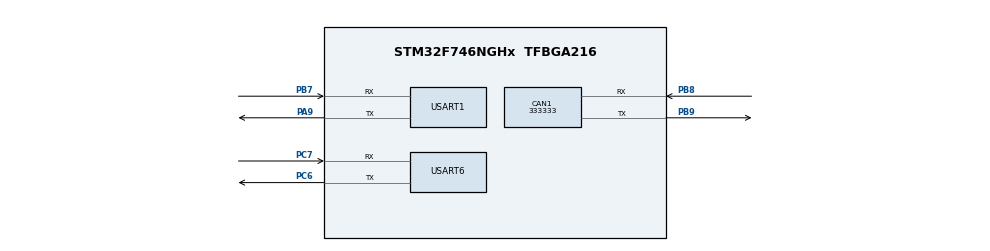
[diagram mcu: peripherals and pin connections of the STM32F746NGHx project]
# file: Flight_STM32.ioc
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CAN1.CalculateBaudRate=333333
CAN1.CalculateTimeBit=3000
CAN1.CalculateTimeQuantum=1000.0
CORTEX_M7.default_mode_Activation=1
Mcu.Family=STM32F7
Mcu.Name=STM32F746NGHx
Mcu.Package=TFBGA216
NVIC.PriorityGroup=NVIC_PRIORITYGROUP_4
NVIC.TIM1_UP_TIM10_IRQn=true\:15\:0\:false\:false\:true\:false\:true\:true
NVIC.TimeBase=TIM1_UP_TIM10_IRQn
NVIC.TimeBaseIP=TIM1
PA9.Mode=Asynchronous
PA9.Signal=USART1_TX
PB7.Mode=Asynchronous
PB7.Signal=USART1_RX
PB8.Mode=CAN_Activate
PB8.Signal=CAN1_RX
PB9.Mode=CAN_Activate
PB9.Signal=CAN1_TX
PC6.Mode=Asynchronous
PC6.Signal=USART6_TX
PC7.Mode=Asynchronous
PC7.Signal=USART6_RX
ProjectManager.HeapSize=0x200
ProjectManager.StackSize=0x400
ProjectManager.TargetToolchain=STM32CubeIDE
RCC.HSE_VALUE=25000000
RCC.HSI_VALUE=16000000
RCC.LSE_VALUE=32768
RCC.USBFreq_Value=96000000
RCC.VCOOutputFreq_Value=192000000
USART1.VirtualMode-Asynchronous=VM_ASYNC
USART6.VirtualMode-Asynchronous=VM_ASYNC
VP_SYS_VS_tim1.Mode=TIM1
board=custom

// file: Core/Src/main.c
/* USER CODE BEGIN Header */
/**
  ******************************************************************************
  * @file           : main.c
  * @brief          : Main program body
  ******************************************************************************
  * @attention
  *
  * Copyright (c) 2025 STMicroelectronics.
  * All rights reserved.
  *
  * This software is licensed under terms that can be found in the LICENSE file
  * in the root directory of this software component.
  * If no LICENSE file comes with this software, it is provided AS-IS.
  *
  ******************************************************************************
  */
/* USER CODE END Header */
#include "main.h"

/* USER CODE BEGIN Includes */
#include "printf.h"
/* USER CODE END Includes */

CAN_HandleTypeDef hcan1;

void SystemClock_Config(void);
static void MPU_Config(void);
static void MX_GPIO_Init(void);
static void MX_USART1_UART_Init(void);
static void MX_USART6_UART_Init(void);
static void MX_CAN1_Init(void);

int main(void)
{

  /* MPU Configuration--------------------------------------------------------*/
  MPU_Config();

  /* MCU Configuration--------------------------------------------------------*/

  /* Reset of all peripherals, Initializes the Flash interface and the Systick. */
  HAL_Init();

  /* Configure the system clock */
  SystemClock_Config();

  /* Initialize all configured peripherals */
  MX_GPIO_Init();
  MX_USART1_UART_Init();
  MX_USART6_UART_Init();
  MX_CAN1_Init();

  /* Infinite loop */
  /* USER CODE BEGIN WHILE */
  app_main();
  while (1)
  {
    /* USER CODE END WHILE */

  }
}

void SystemClock_Config(void)
{
  LL_FLASH_SetLatency(LL_FLASH_LATENCY_0);
  while(LL_FLASH_GetLatency()!= LL_FLASH_LATENCY_0)
  {
  }
  LL_PWR_SetRegulVoltageScaling(LL_PWR_REGU_VOLTAGE_SCALE3);
  LL_PWR_DisableOverDriveMode();
  LL_RCC_HSI_SetCalibTrimming(16);
  LL_RCC_HSI_Enable();

   /* Wait till HSI is ready */
  while(LL_RCC_HSI_IsReady() != 1)
  {

  }
  LL_RCC_SetAHBPrescaler(LL_RCC_SYSCLK_DIV_1);
  LL_RCC_SetAPB1Prescaler(LL_RCC_APB1_DIV_1);
  LL_RCC_SetAPB2Prescaler(LL_RCC_APB2_DIV_1);
  LL_RCC_SetSysClkSource(LL_RCC_SYS_CLKSOURCE_HSI);

   /* Wait till System clock is ready */
  while(LL_RCC_GetSysClkSource() != LL_RCC_SYS_CLKSOURCE_STATUS_HSI)
  {

  }
  LL_SetSystemCoreClock(16000000);

   /* Update the time base */
//  if (HAL_InitTick (TICK_INT_PRIORITY) != HAL_OK)
//  {
//    Error_Handler();
//  }

   /* Set Timers Clock Prescalers */
//  LL_RCC_SetTIMPrescaler(LL_RCC_TIM_PRESCALER_TWICE);
}

static void MX_CAN1_Init(void)
{

  hcan1.Instance = CAN1;
  hcan1.Init.Prescaler = 16;
  hcan1.Init.Mode = CAN_MODE_NORMAL;
  hcan1.Init.SyncJumpWidth = CAN_SJW_1TQ;
  hcan1.Init.TimeSeg1 = CAN_BS1_1TQ;
  hcan1.Init.TimeSeg2 = CAN_BS2_1TQ;
  hcan1.Init.TimeTriggeredMode = DISABLE;
  hcan1.Init.AutoBusOff = DISABLE;
  hcan1.Init.AutoWakeUp = DISABLE;
  hcan1.Init.AutoRetransmission = DISABLE;
  hcan1.Init.ReceiveFifoLocked = DISABLE;
  hcan1.Init.TransmitFifoPriority = DISABLE;
  if (HAL_CAN_Init(&hcan1) != HAL_OK)
  {
    Error_Handler();
  }

}

static void MX_USART1_UART_Init(void)
{

  LL_USART_InitTypeDef USART_InitStruct = {0};

  LL_GPIO_InitTypeDef GPIO_InitStruct = {0};

  LL_RCC_SetUSARTClockSource(LL_RCC_USART1_CLKSOURCE_PCLK2);

  /* Peripheral clock enable */
  LL_APB2_GRP1_EnableClock(LL_APB2_GRP1_PERIPH_USART1);

  LL_AHB1_GRP1_EnableClock(LL_AHB1_GRP1_PERIPH_GPIOB);
  LL_AHB1_GRP1_EnableClock(LL_AHB1_GRP1_PERIPH_GPIOA);
  /**USART1 GPIO Configuration
  PB7   ------> USART1_RX
  PA9   ------> USART1_TX
  */
  GPIO_InitStruct.Pin = LL_GPIO_PIN_7;
  GPIO_InitStruct.Mode = LL_GPIO_MODE_ALTERNATE;
  GPIO_InitStruct.Speed = LL_GPIO_SPEED_FREQ_VERY_HIGH;
  GPIO_InitStruct.OutputType = LL_GPIO_OUTPUT_PUSHPULL;
  GPIO_InitStruct.Pull = LL_GPIO_PULL_NO;
  GPIO_InitStruct.Alternate = LL_GPIO_AF_7;
  LL_GPIO_Init(GPIOB, &GPIO_InitStruct);

  GPIO_InitStruct.Pin = LL_GPIO_PIN_9;
  GPIO_InitStruct.Mode = LL_GPIO_MODE_ALTERNATE;
  GPIO_InitStruct.Speed = LL_GPIO_SPEED_FREQ_VERY_HIGH;
  GPIO_InitStruct.OutputType = LL_GPIO_OUTPUT_PUSHPULL;
  GPIO_InitStruct.Pull = LL_GPIO_PULL_NO;
  GPIO_InitStruct.Alternate = LL_GPIO_AF_7;
  LL_GPIO_Init(GPIOA, &GPIO_InitStruct);

  USART_InitStruct.BaudRate = 115200;
  USART_InitStruct.DataWidth = LL_USART_DATAWIDTH_8B;
  USART_InitStruct.StopBits = LL_USART_STOPBITS_1;
  USART_InitStruct.Parity = LL_USART_PARITY_NONE;
  USART_InitStruct.TransferDirection = LL_USART_DIRECTION_TX_RX;
  USART_InitStruct.HardwareFlowControl = LL_USART_HWCONTROL_NONE;
  USART_InitStruct.OverSampling = LL_USART_OVERSAMPLING_16;
  LL_USART_Init(USART1, &USART_InitStruct);
  LL_USART_ConfigAsyncMode(USART1);
  LL_USART_Enable(USART1);

}

static void MX_USART6_UART_Init(void)
{

  LL_USART_InitTypeDef USART_InitStruct = {0};

  LL_GPIO_InitTypeDef GPIO_InitStruct = {0};

  LL_RCC_SetUSARTClockSource(LL_RCC_USART6_CLKSOURCE_PCLK2);

  /* Peripheral clock enable */
  LL_APB2_GRP1_EnableClock(LL_APB2_GRP1_PERIPH_USART6);

  LL_AHB1_GRP1_EnableClock(LL_AHB1_GRP1_PERIPH_GPIOC);
  /**USART6 GPIO Configuration
  PC7   ------> USART6_RX
  PC6   ------> USART6_TX
  */
  GPIO_InitStruct.Pin = LL_GPIO_PIN_7;
  GPIO_InitStruct.Mode = LL_GPIO_MODE_ALTERNATE;
  GPIO_InitStruct.Speed = LL_GPIO_SPEED_FREQ_VERY_HIGH;
  GPIO_InitStruct.OutputType = LL_GPIO_OUTPUT_PUSHPULL;
  GPIO_InitStruct.Pull = LL_GPIO_PULL_NO;
  GPIO_InitStruct.Alternate = LL_GPIO_AF_8;
  LL_GPIO_Init(GPIOC, &GPIO_InitStruct);

  GPIO_InitStruct.Pin = LL_GPIO_PIN_6;
  GPIO_InitStruct.Mode = LL_GPIO_MODE_ALTERNATE;
  GPIO_InitStruct.Speed = LL_GPIO_SPEED_FREQ_VERY_HIGH;
  GPIO_InitStruct.OutputType = LL_GPIO_OUTPUT_PUSHPULL;
  GPIO_InitStruct.Pull = LL_GPIO_PULL_NO;
  GPIO_InitStruct.Alternate = LL_GPIO_AF_8;
  LL_GPIO_Init(GPIOC, &GPIO_InitStruct);

  USART_InitStruct.BaudRate = 115200;
  USART_InitStruct.DataWidth = LL_USART_DATAWIDTH_8B;
  USART_InitStruct.StopBits = LL_USART_STOPBITS_1;
  USART_InitStruct.Parity = LL_USART_PARITY_NONE;
  USART_InitStruct.TransferDirection = LL_USART_DIRECTION_TX_RX;
  USART_InitStruct.HardwareFlowControl = LL_USART_HWCONTROL_NONE;
  USART_InitStruct.OverSampling = LL_USART_OVERSAMPLING_16;
  LL_USART_Init(USART6, &USART_InitStruct);
  LL_USART_ConfigAsyncMode(USART6);
  LL_USART_Enable(USART6);

}

static void MX_GPIO_Init(void)
{

  /* GPIO Ports Clock Enable */
  LL_AHB1_GRP1_EnableClock(LL_AHB1_GRP1_PERIPH_GPIOB);
  LL_AHB1_GRP1_EnableClock(LL_AHB1_GRP1_PERIPH_GPIOA);
  LL_AHB1_GRP1_EnableClock(LL_AHB1_GRP1_PERIPH_GPIOC);

}

 /* MPU Configuration */

void MPU_Config(void)
{

  /* Disables the MPU */
  LL_MPU_Disable();

  /** Initializes and configures the Region and the memory to be protected
  */
  LL_MPU_ConfigRegion(LL_MPU_REGION_NUMBER0, 0x87, 0x0, LL_MPU_REGION_SIZE_4GB|LL_MPU_TEX_LEVEL0|LL_MPU_REGION_NO_ACCESS|LL_MPU_INSTRUCTION_ACCESS_DISABLE|LL_MPU_ACCESS_SHAREABLE|LL_MPU_ACCESS_NOT_CACHEABLE|LL_MPU_ACCESS_NOT_BUFFERABLE);
  /* Enables the MPU */
  LL_MPU_Enable(LL_MPU_CTRL_PRIVILEGED_DEFAULT);

}

void HAL_TIM_PeriodElapsedCallback(TIM_HandleTypeDef *htim)
{
  if (htim->Instance == TIM1)
  {
    HAL_IncTick();
  }
}

void Error_Handler(void)
{
  __disable_irq();
  while (1)
  {
  }
}
